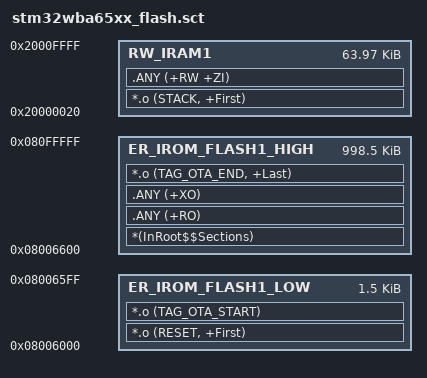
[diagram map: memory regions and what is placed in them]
; *************************************************************
; *** Scatter-Loading Description File                      ***
; *************************************************************

LR_IROM_FLASH1 0x08006000 0x600 {
  ER_IROM_FLASH1_LOW 0x08006000 0x600 {
    *.o (RESET, +First)
    *.o (TAG_OTA_START)
  }

  RW_IRAM1 0x20000020 0x0FFE0 {
    *.o (STACK, +First)
    .ANY (+RW +ZI)
  }
}

LR_IROM_FLASH2 0x08006600 0xF9A00 {
  ER_IROM_FLASH1_HIGH 0x08006600 0xF9A00 {
    *(InRoot$$Sections)
    .ANY (+RO)
    .ANY (+XO)
    *.o (TAG_OTA_END, +Last)
  }
}
